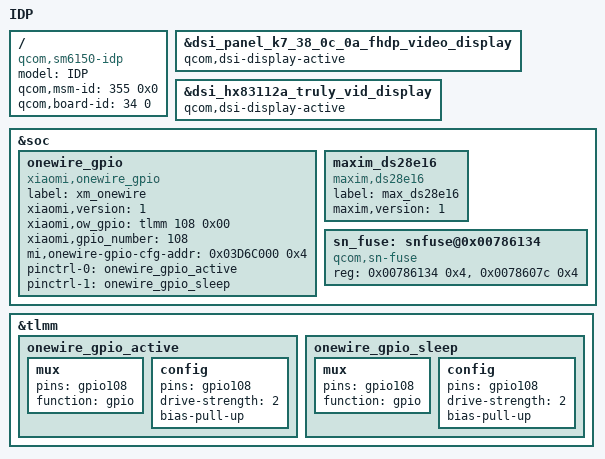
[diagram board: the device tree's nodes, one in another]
/* Copyright (c) 2018, The Linux Foundation. All rights reserved.
 * Copyright (C) 2021 XiaoMi, Inc.
 *
 * This program is free software; you can redistribute it and/or modify
 * it under the terms of the GNU General Public License version 2 and
 * only version 2 as published by the Free Software Foundation.
 *
 * This program is distributed in the hope that it will be useful,
 * but WITHOUT ANY WARRANTY; without even the implied warranty of
 * MERCHANTABILITY or FITNESS FOR A PARTICULAR PURPOSE.  See the
 * GNU General Public License for more details.
 */

/dts-v1/;
/plugin/;

#include <dt-bindings/interrupt-controller/arm-gic.h>
#include <dt-bindings/clock/qcom,camcc-sm6150.h>
#include "touchscreen.dtsi"

#include "sm6150-idp.dtsi"
#include "sm6150-audio-overlay.dtsi"

/ {
	model = "IDP";
	compatible = "qcom,sm6150-idp", "qcom,sm6150", "qcom,idp";
	qcom,msm-id = <355 0x0>;
	qcom,board-id = <34 0>;
};

&dsi_panel_k7_38_0c_0a_fhdp_video_display {
	qcom,dsi-display-active;
};

&dsi_hx83112a_truly_vid_display {
	qcom,dsi-display-active;
};

&soc {
	onewire_gpio: onewire_gpio {
		compatible = "xiaomi,onewire_gpio";
		label = "xm_onewire";
		xiaomi,version = <1>;
		xiaomi,ow_gpio = <&tlmm 108  0x00>;
		xiaomi,gpio_number = <108>;
		mi,onewire-gpio-cfg-addr = <0x03D6C000 0x4>;
		pinctrl-names = "onewire_active", "onewire_sleep";
		pinctrl-0 = <&onewire_gpio_active>;
		pinctrl-1 = <&onewire_gpio_sleep>;
		status = "ok";
	};

	maxim_ds28e16: maxim_ds28e16 {
		compatible = "maxim,ds28e16";
		label = "max_ds28e16";
		maxim,version = <1>;
		status = "ok";
	};

	sn_fuse: snfuse@0x00786134 {
		compatible = "qcom,sn-fuse";
		reg = <0x00786134 0x4>,
			<0x0078607c 0x4>;
		reg-names = "sn-base","fuse-state";
	};
};

&tlmm {
	onewire_gpio_active: onewire_gpio_active {
		mux {
			pins = "gpio108";
			function = "gpio";
		};

		config {
			pins = "gpio108";
			drive-strength = <2>;
			bias-pull-up;
		};
	};

	onewire_gpio_sleep: onewire_gpio_sleep {
		mux {
			pins = "gpio108";
			function = "gpio";
		};

		config {
			pins = "gpio108";
			drive-strength = <2>;
			bias-pull-up;
		};
	};
};
